# iom480ae register map
Registers are 32-bit, access not given, no defined reset value unless marked. A register's access mark holds for its fields unless they carry their own. Addresses are absolute; registers are grouped by the start of their names; [hi:lo] are bit positions; {n}, {i} and the like mark numbered series.

## GPIO
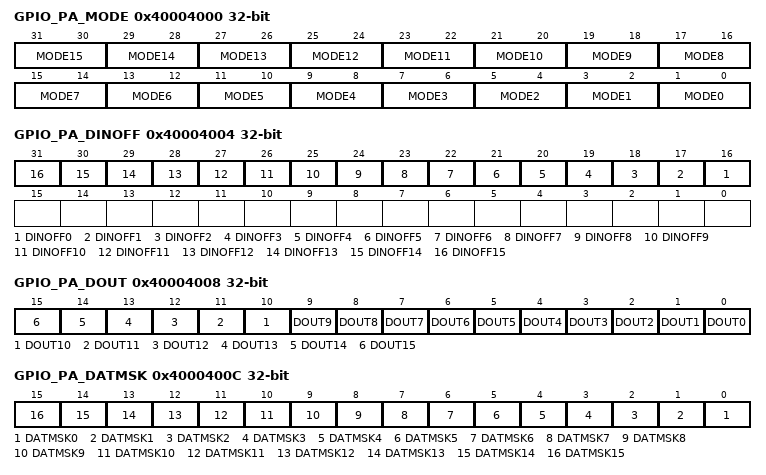
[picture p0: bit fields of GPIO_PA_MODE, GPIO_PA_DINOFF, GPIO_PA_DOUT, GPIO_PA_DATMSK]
0x40004000 GPIO_PA_MODE
  [2n+1:2n] MODE{n} (n=0..15)
0x40004004 GPIO_PA_DINOFF
  [n+16] DINOFF{n} (n=0..15)
0x40004008 GPIO_PA_DOUT
  [n] DOUT{n} (n=0..15)
0x4000400C GPIO_PA_DATMSK
  [n] DATMSK{n} (n=0..15)
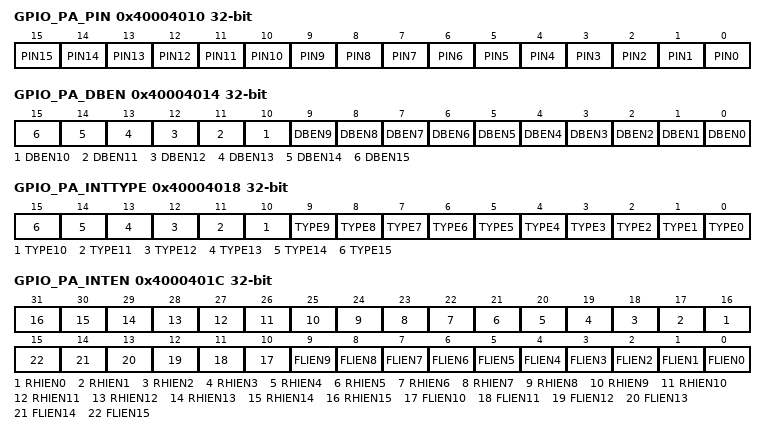
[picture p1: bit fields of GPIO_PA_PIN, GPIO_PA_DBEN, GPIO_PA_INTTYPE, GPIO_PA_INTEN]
0x40004010 GPIO_PA_PIN
  [n] PIN{n} (n=0..15)
0x40004014 GPIO_PA_DBEN
  [n] DBEN{n} (n=0..15)
0x40004018 GPIO_PA_INTTYPE
  [n] TYPE{n} (n=0..15)
0x4000401C GPIO_PA_INTEN
  [n+16] RHIEN{n} (n=0..15), [n] FLIEN{n} (n=0..15)
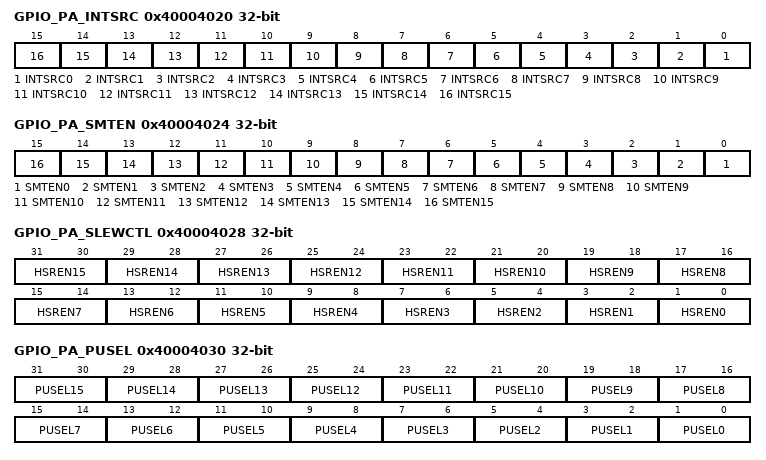
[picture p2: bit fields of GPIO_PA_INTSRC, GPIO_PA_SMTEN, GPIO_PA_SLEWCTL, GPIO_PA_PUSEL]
0x40004020 GPIO_PA_INTSRC
  [n] INTSRC{n} (n=0..15)
0x40004024 GPIO_PA_SMTEN
  [n] SMTEN{n} (n=0..15)
0x40004028 GPIO_PA_SLEWCTL
  [2n+1:2n] HSREN{n} (n=0..15)
0x40004030 GPIO_PA_PUSEL
  [2n+1:2n] PUSEL{n} (n=0..15)
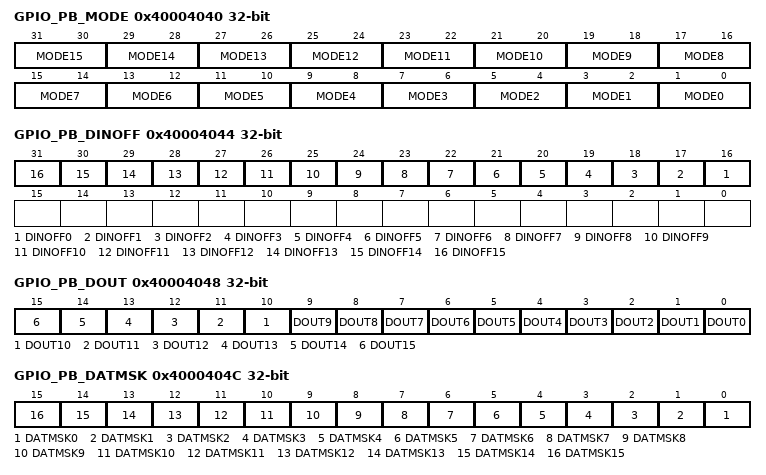
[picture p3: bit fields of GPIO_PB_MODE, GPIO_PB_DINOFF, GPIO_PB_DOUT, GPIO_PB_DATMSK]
0x40004040 GPIO_PB_MODE
  [2n+1:2n] MODE{n} (n=0..15)
0x40004044 GPIO_PB_DINOFF
  [n+16] DINOFF{n} (n=0..15)
0x40004048 GPIO_PB_DOUT
  [n] DOUT{n} (n=0..15)
0x4000404C GPIO_PB_DATMSK
  [n] DATMSK{n} (n=0..15)
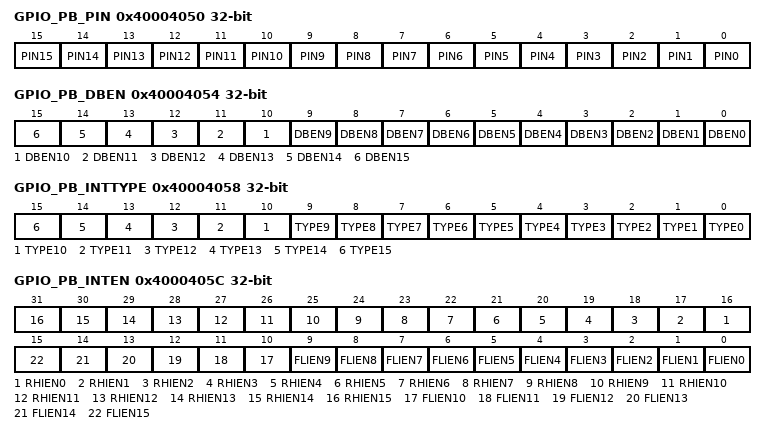
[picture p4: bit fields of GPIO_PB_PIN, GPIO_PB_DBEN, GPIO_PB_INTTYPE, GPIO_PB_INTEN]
0x40004050 GPIO_PB_PIN
  [n] PIN{n} (n=0..15)
0x40004054 GPIO_PB_DBEN
  [n] DBEN{n} (n=0..15)
0x40004058 GPIO_PB_INTTYPE
  [n] TYPE{n} (n=0..15)
0x4000405C GPIO_PB_INTEN
  [n+16] RHIEN{n} (n=0..15), [n] FLIEN{n} (n=0..15)
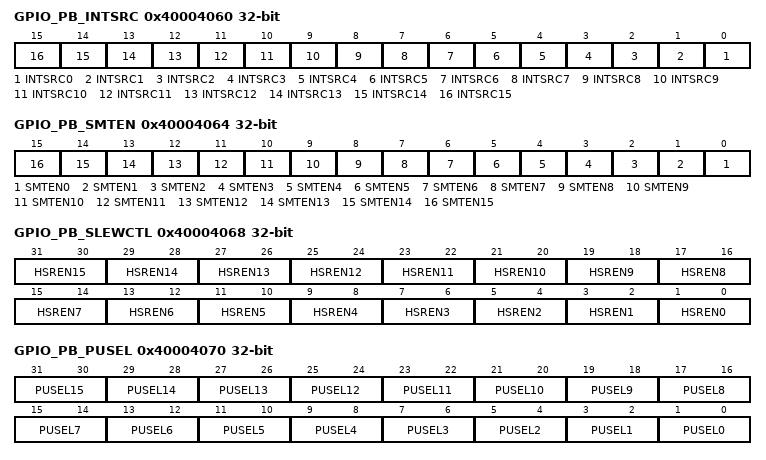
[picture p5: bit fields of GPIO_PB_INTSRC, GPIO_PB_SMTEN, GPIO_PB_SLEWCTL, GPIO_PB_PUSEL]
0x40004060 GPIO_PB_INTSRC
  [n] INTSRC{n} (n=0..15)
0x40004064 GPIO_PB_SMTEN
  [n] SMTEN{n} (n=0..15)
0x40004068 GPIO_PB_SLEWCTL
  [2n+1:2n] HSREN{n} (n=0..15)
0x40004070 GPIO_PB_PUSEL
  [2n+1:2n] PUSEL{n} (n=0..15)
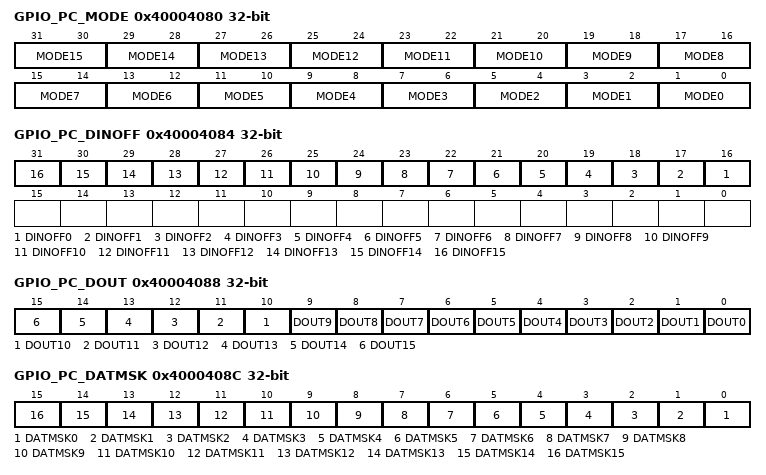
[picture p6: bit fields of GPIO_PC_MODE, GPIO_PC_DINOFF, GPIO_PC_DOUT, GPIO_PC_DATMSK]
0x40004080 GPIO_PC_MODE
  [2n+1:2n] MODE{n} (n=0..15)
0x40004084 GPIO_PC_DINOFF
  [n+16] DINOFF{n} (n=0..15)
0x40004088 GPIO_PC_DOUT
  [n] DOUT{n} (n=0..15)
0x4000408C GPIO_PC_DATMSK
  [n] DATMSK{n} (n=0..15)
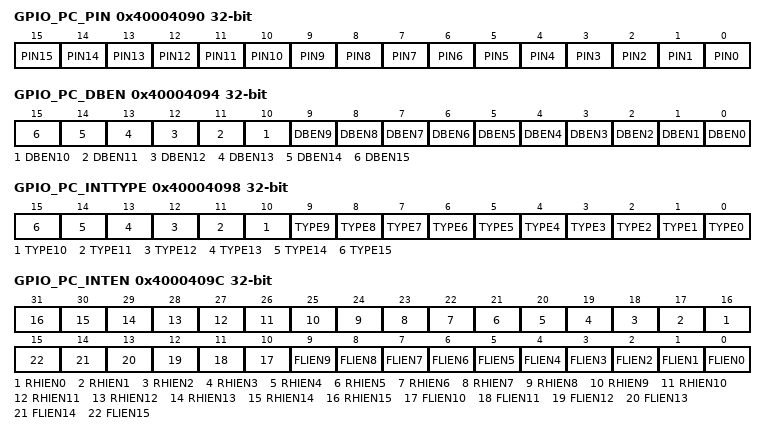
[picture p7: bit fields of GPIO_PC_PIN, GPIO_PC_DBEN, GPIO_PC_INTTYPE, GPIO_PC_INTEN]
0x40004090 GPIO_PC_PIN
  [n] PIN{n} (n=0..15)
0x40004094 GPIO_PC_DBEN
  [n] DBEN{n} (n=0..15)
0x40004098 GPIO_PC_INTTYPE
  [n] TYPE{n} (n=0..15)
0x4000409C GPIO_PC_INTEN
  [n+16] RHIEN{n} (n=0..15), [n] FLIEN{n} (n=0..15)
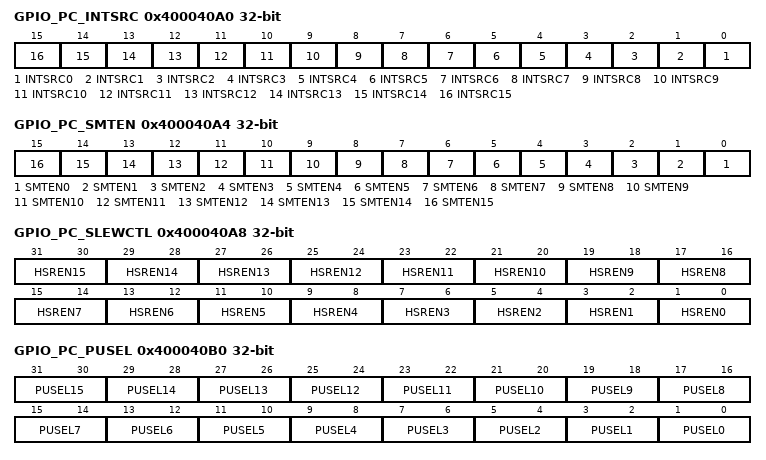
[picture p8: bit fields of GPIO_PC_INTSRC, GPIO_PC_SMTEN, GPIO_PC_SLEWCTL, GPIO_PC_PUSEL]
0x400040A0 GPIO_PC_INTSRC
  [n] INTSRC{n} (n=0..15)
0x400040A4 GPIO_PC_SMTEN
  [n] SMTEN{n} (n=0..15)
0x400040A8 GPIO_PC_SLEWCTL
  [2n+1:2n] HSREN{n} (n=0..15)
0x400040B0 GPIO_PC_PUSEL
  [2n+1:2n] PUSEL{n} (n=0..15)
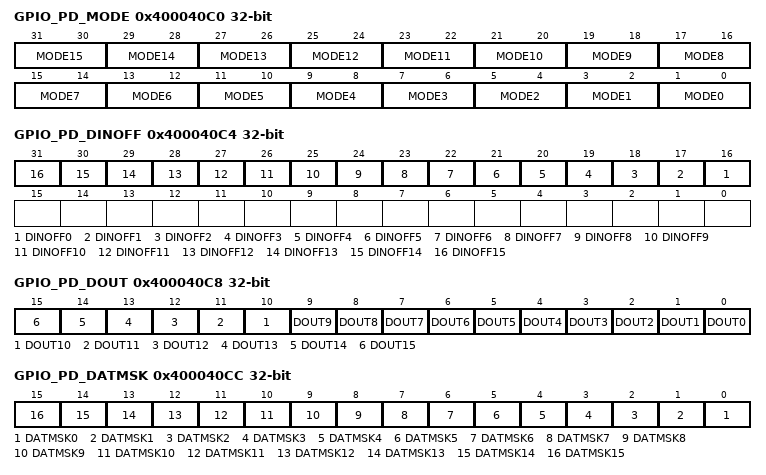
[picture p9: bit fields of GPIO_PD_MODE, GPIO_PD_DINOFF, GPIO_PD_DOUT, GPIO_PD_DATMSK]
0x400040C0 GPIO_PD_MODE
  [2n+1:2n] MODE{n} (n=0..15)
0x400040C4 GPIO_PD_DINOFF
  [n+16] DINOFF{n} (n=0..15)
0x400040C8 GPIO_PD_DOUT
  [n] DOUT{n} (n=0..15)
0x400040CC GPIO_PD_DATMSK
  [n] DATMSK{n} (n=0..15)
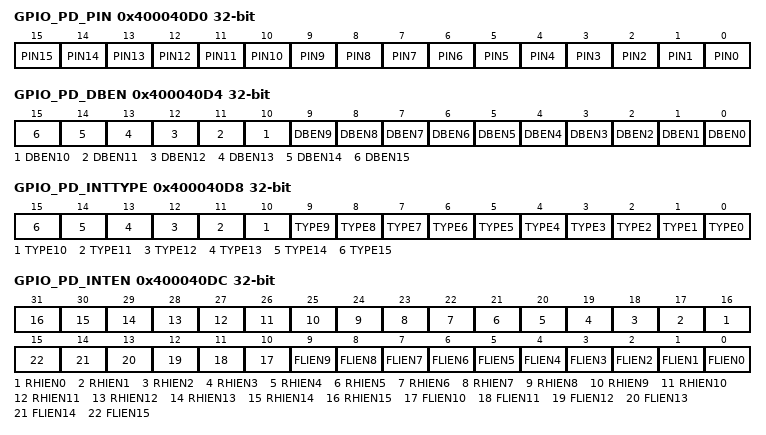
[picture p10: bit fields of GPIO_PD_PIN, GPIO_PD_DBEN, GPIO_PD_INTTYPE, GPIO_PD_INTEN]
0x400040D0 GPIO_PD_PIN
  [n] PIN{n} (n=0..15)
0x400040D4 GPIO_PD_DBEN
  [n] DBEN{n} (n=0..15)
0x400040D8 GPIO_PD_INTTYPE
  [n] TYPE{n} (n=0..15)
0x400040DC GPIO_PD_INTEN
  [n+16] RHIEN{n} (n=0..15), [n] FLIEN{n} (n=0..15)
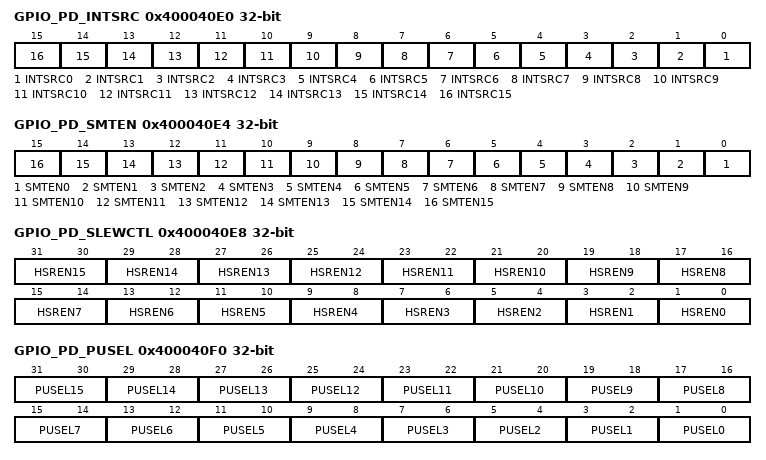
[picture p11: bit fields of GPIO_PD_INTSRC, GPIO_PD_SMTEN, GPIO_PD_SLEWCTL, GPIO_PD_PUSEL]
0x400040E0 GPIO_PD_INTSRC
  [n] INTSRC{n} (n=0..15)
0x400040E4 GPIO_PD_SMTEN
  [n] SMTEN{n} (n=0..15)
0x400040E8 GPIO_PD_SLEWCTL
  [2n+1:2n] HSREN{n} (n=0..15)
0x400040F0 GPIO_PD_PUSEL
  [2n+1:2n] PUSEL{n} (n=0..15)
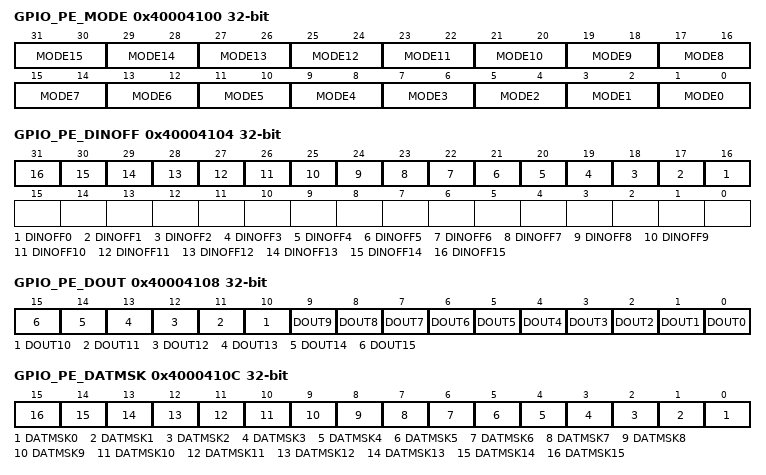
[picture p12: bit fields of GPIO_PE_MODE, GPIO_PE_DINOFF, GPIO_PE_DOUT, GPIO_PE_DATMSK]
0x40004100 GPIO_PE_MODE
  [2n+1:2n] MODE{n} (n=0..15)
0x40004104 GPIO_PE_DINOFF
  [n+16] DINOFF{n} (n=0..15)
0x40004108 GPIO_PE_DOUT
  [n] DOUT{n} (n=0..15)
0x4000410C GPIO_PE_DATMSK
  [n] DATMSK{n} (n=0..15)
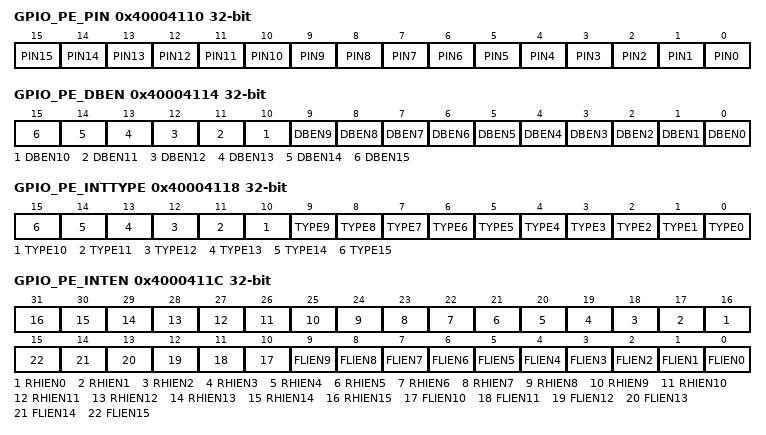
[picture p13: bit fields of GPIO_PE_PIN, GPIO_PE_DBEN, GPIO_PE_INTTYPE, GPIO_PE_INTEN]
0x40004110 GPIO_PE_PIN
  [n] PIN{n} (n=0..15)
0x40004114 GPIO_PE_DBEN
  [n] DBEN{n} (n=0..15)
0x40004118 GPIO_PE_INTTYPE
  [n] TYPE{n} (n=0..15)
0x4000411C GPIO_PE_INTEN
  [n+16] RHIEN{n} (n=0..15), [n] FLIEN{n} (n=0..15)
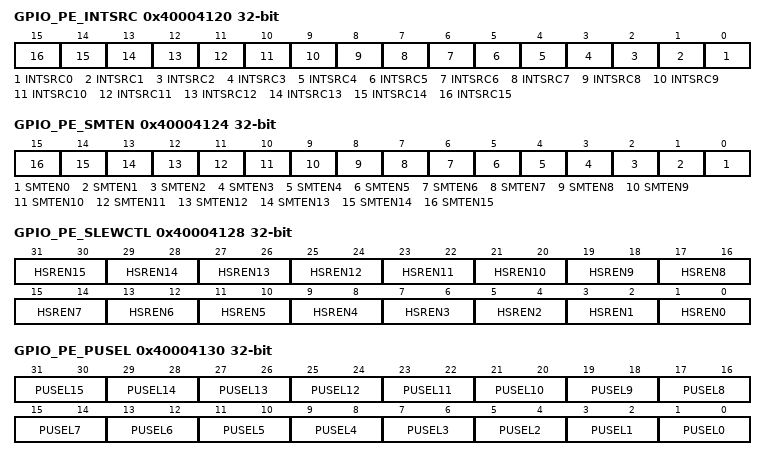
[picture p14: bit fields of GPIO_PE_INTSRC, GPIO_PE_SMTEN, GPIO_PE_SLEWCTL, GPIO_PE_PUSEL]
0x40004120 GPIO_PE_INTSRC
  [n] INTSRC{n} (n=0..15)
0x40004124 GPIO_PE_SMTEN
  [n] SMTEN{n} (n=0..15)
0x40004128 GPIO_PE_SLEWCTL
  [2n+1:2n] HSREN{n} (n=0..15)
0x40004130 GPIO_PE_PUSEL
  [2n+1:2n] PUSEL{n} (n=0..15)
0x40004140 GPIO_PF_MODE
  [2n+1:2n] MODE{n} (n=0..15)
0x40004144 GPIO_PF_DINOFF
  [n+16] DINOFF{n} (n=0..15)
0x40004148 GPIO_PF_DOUT
  [n] DOUT{n} (n=0..15)
0x4000414C GPIO_PF_DATMSK
  [n] DATMSK{n} (n=0..15)
0x40004150 GPIO_PF_PIN
  [n] PIN{n} (n=0..15)
0x40004154 GPIO_PF_DBEN
  [n] DBEN{n} (n=0..15)
0x40004158 GPIO_PF_INTTYPE
  [n] TYPE{n} (n=0..15)
0x4000415C GPIO_PF_INTEN
  [n+16] RHIEN{n} (n=0..15), [n] FLIEN{n} (n=0..15)
0x40004160 GPIO_PF_INTSRC
  [n] INTSRC{n} (n=0..15)
0x40004164 GPIO_PF_SMTEN
  [n] SMTEN{n} (n=0..15)
0x40004168 GPIO_PF_SLEWCTL
  [2n+1:2n] HSREN{n} (n=0..15)
0x40004170 GPIO_PF_PUSEL
  [2n+1:2n] PUSEL{n} (n=0..15)
0x40004180 GPIO_PG_MODE
  [2n+1:2n] MODE{n} (n=0..15)
0x40004184 GPIO_PG_DINOFF
  [n+16] DINOFF{n} (n=0..15)
0x40004188 GPIO_PG_DOUT
  [n] DOUT{n} (n=0..15)
0x4000418C GPIO_PG_DATMSK
  [n] DATMSK{n} (n=0..15)
0x40004190 GPIO_PG_PIN
  [n] PIN{n} (n=0..15)
0x40004194 GPIO_PG_DBEN
  [n] DBEN{n} (n=0..15)
0x40004198 GPIO_PG_INTTYPE
  [n] TYPE{n} (n=0..15)
0x4000419C GPIO_PG_INTEN
  [n+16] RHIEN{n} (n=0..15), [n] FLIEN{n} (n=0..15)
0x400041A0 GPIO_PG_INTSRC
  [n] INTSRC{n} (n=0..15)
0x400041A4 GPIO_PG_SMTEN
  [n] SMTEN{n} (n=0..15)
0x400041A8 GPIO_PG_SLEWCTL
  [2n+1:2n] HSREN{n} (n=0..15)
0x400041B0 GPIO_PG_PUSEL
  [2n+1:2n] PUSEL{n} (n=0..15)
0x400041C0 GPIO_PH_MODE
  [2n+1:2n] MODE{n} (n=0..15)
0x400041C4 GPIO_PH_DINOFF
  [n+16] DINOFF{n} (n=0..15)
0x400041C8 GPIO_PH_DOUT
  [n] DOUT{n} (n=0..15)
0x400041CC GPIO_PH_DATMSK
  [n] DATMSK{n} (n=0..15)
0x400041D0 GPIO_PH_PIN
  [n] PIN{n} (n=0..15)
0x400041D4 GPIO_PH_DBEN
  [n] DBEN{n} (n=0..15)
0x400041D8 GPIO_PH_INTTYPE
  [n] TYPE{n} (n=0..15)
0x400041DC GPIO_PH_INTEN
  [n+16] RHIEN{n} (n=0..15), [n] FLIEN{n} (n=0..15)
0x400041E0 GPIO_PH_INTSRC
  [n] INTSRC{n} (n=0..15)
0x400041E4 GPIO_PH_SMTEN
  [n] SMTEN{n} (n=0..15)
0x400041E8 GPIO_PH_SLEWCTL
  [2n+1:2n] HSREN{n} (n=0..15)
0x400041F0 GPIO_PH_PUSEL
  [2n+1:2n] PUSEL{n} (n=0..15)
0x40004440 GPIO_GPIO_DBCTL
  [5] ICLKON, [4] DBCLKSRC, [3:0] DBCLKSEL
{0x40004800+4i} GPIO_PA{i}_PDIO (i=0..15)
  [0] PDIO
{0x40004840+4i} GPIO_PB{i}_PDIO (i=0..15)
  [0] PDIO
{0x40004880+4i} GPIO_PC{i}_PDIO (i=0..15)
  [0] PDIO
{0x400048C0+4i} GPIO_PD{i}_PDIO (i=0..15)
  [0] PDIO
{0x40004900+4i} GPIO_PE{i}_PDIO (i=0..15)
  [0] PDIO
{0x40004940+4i} GPIO_PF{i}_PDIO (i=0..15)
  [0] PDIO
{0x40004980+4i} GPIO_PG{i}_PDIO (i=0..12)
  [0] PDIO
{0x400049C0+4i} GPIO_PH{i}_PDIO (i=0..12)
  [0] PDIO
